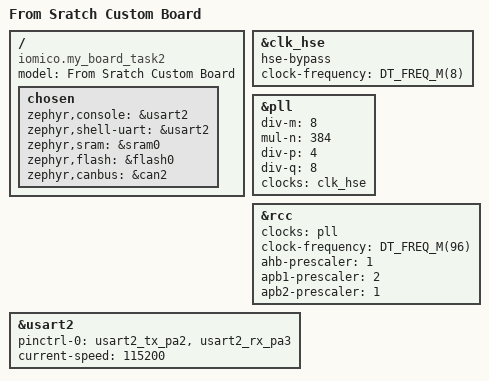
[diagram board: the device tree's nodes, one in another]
/dts-v1/;
#include <st/f4/stm32f446Xe.dtsi>
#include <st/f4/stm32f446r(c-e)tx-pinctrl.dtsi>
#include "arduino_r3_connector.dtsi"
#include "st_morpho_connector.dtsi"
#include <zephyr/dt-bindings/input/input-event-codes.h>

/{
    model = "From Sratch Custom Board";
	compatible = "iomico.my_board_task2";

	chosen {
		zephyr,console = &usart2;
		zephyr,shell-uart = &usart2;
		zephyr,sram = &sram0;
		zephyr,flash = &flash0;
		zephyr,canbus = &can2;
	};
};

&clk_hse {
    hse-bypass;
    clock-frequency = <DT_FREQ_M(8)>;
    status = "okay";
};

&pll {
    div-m = <8>;
    mul-n = <384>;
    div-p = <4>;
    div-q = <8>;
    clocks = <&clk_hse>;
    status = "okay";
};

&rcc {
    clocks = <&pll>;
    clock-frequency = <DT_FREQ_M(96)>;
    ahb-prescaler = <1>;
    apb1-prescaler = <2>;
    apb2-prescaler = <1>;
};

&usart2 {
    pinctrl-0 = <&usart2_tx_pa2 &usart2_rx_pa3>;
    pinctrl-names = "default";
    current-speed = <115200>;
    status = "okay";
};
